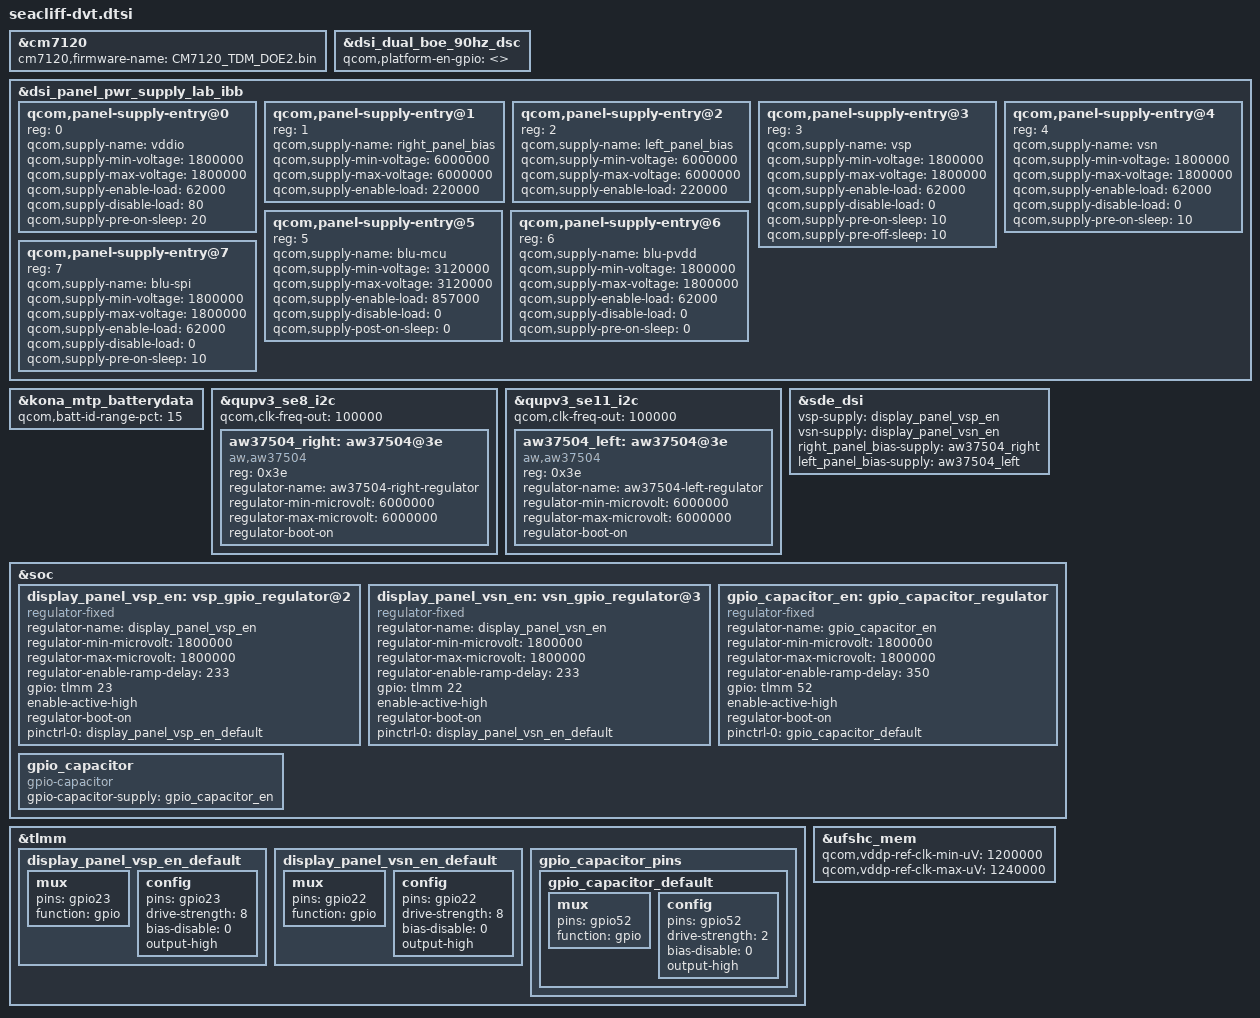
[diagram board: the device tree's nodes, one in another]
// SPDX-License-Identifier: GPL-2.0

#include "seacliff.dtsi"
#include "seacliff-adc-usbc.dtsi"

&cm7120 {
	cm7120,firmware-name = "CM7120_TDM_DOE2.bin";
};

&dsi_dual_boe_90hz_dsc {
	qcom,platform-en-gpio = <>;
};

&dsi_panel_pwr_supply_lab_ibb {
	qcom,panel-supply-entry@0 {
		reg = <0>;
		qcom,supply-name = "vddio";
		qcom,supply-min-voltage = <1800000>;
		qcom,supply-max-voltage = <1800000>;
		qcom,supply-enable-load = <62000>;
		qcom,supply-disable-load = <80>;
		qcom,supply-pre-on-sleep = <20>;
	};

	qcom,panel-supply-entry@1 {
		reg = <1>;
		qcom,supply-name = "right_panel_bias";
		qcom,supply-min-voltage = <6000000>;
		qcom,supply-max-voltage = <6000000>;
		qcom,supply-enable-load = <220000>;
	};

	qcom,panel-supply-entry@2 {
		reg = <2>;
		qcom,supply-name = "left_panel_bias";
		qcom,supply-min-voltage = <6000000>;
		qcom,supply-max-voltage = <6000000>;
		qcom,supply-enable-load = <220000>;
	};

	qcom,panel-supply-entry@3 {
		reg = <3>;
		qcom,supply-name = "vsp";
		qcom,supply-min-voltage = <1800000>;
		qcom,supply-max-voltage = <1800000>;
		qcom,supply-enable-load = <62000>;
		qcom,supply-disable-load = <0>;
		qcom,supply-pre-on-sleep = <10>;
		qcom,supply-pre-off-sleep = <10>;
	};

	qcom,panel-supply-entry@4 {
		reg = <4>;
		qcom,supply-name = "vsn";
		qcom,supply-min-voltage = <1800000>;
		qcom,supply-max-voltage = <1800000>;
		qcom,supply-enable-load = <62000>;
		qcom,supply-disable-load = <0>;
		qcom,supply-pre-on-sleep = <10>;
	};

	qcom,panel-supply-entry@5 {
		reg = <5>;
		qcom,supply-name = "blu-mcu";
		qcom,supply-min-voltage = <3120000>;
		qcom,supply-max-voltage = <3120000>;
		qcom,supply-enable-load = <857000>;
		qcom,supply-disable-load = <0>;
		qcom,supply-post-on-sleep = <0>;
	};

	qcom,panel-supply-entry@6 {
		reg = <6>;
		qcom,supply-name = "blu-pvdd";
		qcom,supply-min-voltage = <1800000>;
		qcom,supply-max-voltage = <1800000>;
		qcom,supply-enable-load = <62000>;
		qcom,supply-disable-load = <0>;
		qcom,supply-pre-on-sleep = <0>;
	};

	qcom,panel-supply-entry@7 {
		reg = <7>;
		qcom,supply-name = "blu-spi";
		qcom,supply-min-voltage = <1800000>;
		qcom,supply-max-voltage = <1800000>;
		qcom,supply-enable-load = <62000>;
		qcom,supply-disable-load = <0>;
		qcom,supply-pre-on-sleep = <10>;
	};
};

&kona_mtp_batterydata {
	qcom,batt-id-range-pct = <15>;
	#include "5854977_Meta_Seacliff_5514mAH_averaged_MasterSlave_Jun30th2022.dtsi"
};

&qupv3_se8_i2c {
	status = "ok";
	qcom,clk-freq-out = <100000>;

	aw37504_right: aw37504@3e {
		compatible = "aw,aw37504";
		reg = <0x3e>;
		status = "ok";

		regulator-name = "aw37504-right-regulator";
		regulator-min-microvolt = <6000000>;
		regulator-max-microvolt = <6000000>;
		regulator-boot-on;
	};
};

&qupv3_se11_i2c {
	status = "ok";
	qcom,clk-freq-out = <100000>;

	aw37504_left: aw37504@3e {
		compatible = "aw,aw37504";
		reg = <0x3e>;
		status = "ok";

		regulator-name = "aw37504-left-regulator";
		regulator-min-microvolt = <6000000>;
		regulator-max-microvolt = <6000000>;
		regulator-boot-on;
	};
};

&sde_dsi {
	vsp-supply = <&display_panel_vsp_en>;
	vsn-supply = <&display_panel_vsn_en>;

	right_panel_bias-supply = <&aw37504_right>;
	left_panel_bias-supply = <&aw37504_left>;
};

&soc {
	display_panel_vsp_en: vsp_gpio_regulator@2 {
		compatible = "regulator-fixed";
		regulator-name = "display_panel_vsp_en";
		regulator-min-microvolt = <1800000>;
		regulator-max-microvolt = <1800000>;
		regulator-enable-ramp-delay = <233>;
		gpio = <&tlmm 23 0>;
		enable-active-high;
		regulator-boot-on;
		pinctrl-names = "default";
		pinctrl-0 = <&display_panel_vsp_en_default>;
	};

	display_panel_vsn_en: vsn_gpio_regulator@3 {
		compatible = "regulator-fixed";
		regulator-name = "display_panel_vsn_en";
		regulator-min-microvolt = <1800000>;
		regulator-max-microvolt = <1800000>;
		regulator-enable-ramp-delay = <233>;
		gpio = <&tlmm 22 0>;
		enable-active-high;
		regulator-boot-on;
		pinctrl-names = "default";
		pinctrl-0 = <&display_panel_vsn_en_default>;
	};

	gpio_capacitor_en: gpio_capacitor_regulator {
		compatible = "regulator-fixed";
		regulator-name = "gpio_capacitor_en";
		regulator-min-microvolt = <1800000>;
		regulator-max-microvolt = <1800000>;
		regulator-enable-ramp-delay = <350>;
		gpio = <&tlmm 52 0>;
		enable-active-high;
		regulator-boot-on;
		pinctrl-names = "default";
		pinctrl-0 = <&gpio_capacitor_default>;
	};

	gpio_capacitor {
		compatible = "gpio-capacitor";
		gpio-capacitor-supply = <&gpio_capacitor_en>;
	};
};

&tlmm {
	display_panel_vsp_en_default: display_panel_vsp_en_default {
		mux {
			pins = "gpio23";
			function = "gpio";
		};

		config {
			pins = "gpio23";
			drive-strength = <8>;
			bias-disable = <0>;
			output-high;
		};
	};

	display_panel_vsn_en_default: display_panel_vsn_en_default {
		mux {
			pins = "gpio22";
			function = "gpio";
		};

		config {
			pins = "gpio22";
			drive-strength = <8>;
			bias-disable = <0>;
			output-high;
		};
	};

	gpio_capacitor_pins {
		gpio_capacitor_default: gpio_capacitor_default {
			mux {
				pins = "gpio52";
				function = "gpio";
			};

			config {
				pins = "gpio52";
				drive-strength = <2>;
				bias-disable = <0>;
				output-high;
			};
		};
	};
};

&ufshc_mem {
	qcom,vddp-ref-clk-min-uV = <1200000>;
	qcom,vddp-ref-clk-max-uV = <1240000>;
};
